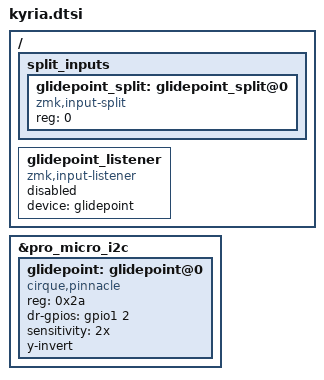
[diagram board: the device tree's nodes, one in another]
/ {
    split_inputs {
        #address-cells = <1>;
        #size-cells = <0>;

        glidepoint_split: glidepoint_split@0 {
            compatible = "zmk,input-split";
            reg = <0>;
        };
    };

    glidepoint_listener: glidepoint_listener {
        compatible = "zmk,input-listener";
        status = "disabled";
        device = <&glidepoint>;
    };
};

&pro_micro_i2c {
    status = "okay";

    glidepoint: glidepoint@0 {
        compatible = "cirque,pinnacle";
        reg = <0x2a>;
        status = "okay";
        dr-gpios = <&gpio1 2 (GPIO_ACTIVE_HIGH)>;

        sensitivity = "2x";
        y-invert;
    };
};

